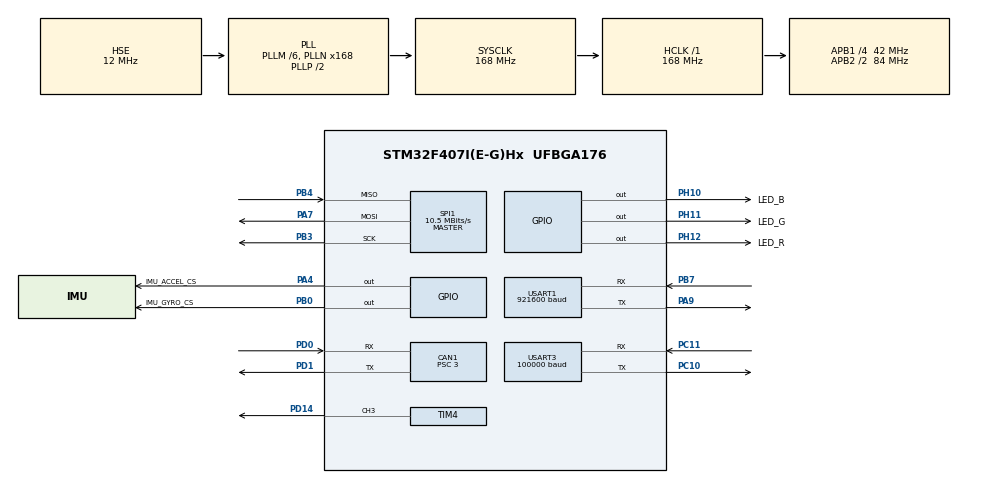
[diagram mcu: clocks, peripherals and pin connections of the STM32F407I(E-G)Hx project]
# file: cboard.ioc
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CAN1.BS1=CAN_BS1_10TQ
CAN1.BS2=CAN_BS2_3TQ
CAN1.CalculateBaudRate=1000000
CAN1.CalculateTimeQuantum=71.42857142857143
CAN1.NART=ENABLE
CAN1.Prescaler=3
CAN1.TXFP=ENABLE
Dma.Request0=USART1_TX
Dma.Request1=USART1_RX
Dma.Request2=USART3_RX
Dma.USART1_TX.0.Direction=DMA_MEMORY_TO_PERIPH
Dma.USART1_TX.0.FIFOMode=DMA_FIFOMODE_DISABLE
Dma.USART1_TX.0.Instance=DMA2_Stream7
Dma.USART1_TX.0.MemDataAlignment=DMA_MDATAALIGN_BYTE
Dma.USART1_TX.0.MemInc=DMA_MINC_ENABLE
Dma.USART1_TX.0.Mode=DMA_NORMAL
Dma.USART1_TX.0.PeriphDataAlignment=DMA_PDATAALIGN_BYTE
Dma.USART1_TX.0.PeriphInc=DMA_PINC_DISABLE
Dma.USART1_TX.0.Priority=DMA_PRIORITY_VERY_HIGH
Dma.USART1_RX.1.Direction=DMA_PERIPH_TO_MEMORY
Dma.USART1_RX.1.FIFOMode=DMA_FIFOMODE_DISABLE
Dma.USART1_RX.1.Instance=DMA2_Stream5
Dma.USART1_RX.1.MemDataAlignment=DMA_MDATAALIGN_BYTE
Dma.USART1_RX.1.MemInc=DMA_MINC_ENABLE
Dma.USART1_RX.1.Mode=DMA_NORMAL
Dma.USART1_RX.1.PeriphDataAlignment=DMA_PDATAALIGN_BYTE
Dma.USART1_RX.1.PeriphInc=DMA_PINC_DISABLE
Dma.USART1_RX.1.Priority=DMA_PRIORITY_VERY_HIGH
Dma.USART3_RX.2.Direction=DMA_PERIPH_TO_MEMORY
Dma.USART3_RX.2.FIFOMode=DMA_FIFOMODE_DISABLE
Dma.USART3_RX.2.Instance=DMA1_Stream1
Dma.USART3_RX.2.MemDataAlignment=DMA_MDATAALIGN_BYTE
Dma.USART3_RX.2.MemInc=DMA_MINC_ENABLE
Dma.USART3_RX.2.Mode=DMA_NORMAL
Dma.USART3_RX.2.PeriphDataAlignment=DMA_PDATAALIGN_BYTE
Dma.USART3_RX.2.PeriphInc=DMA_PINC_DISABLE
Dma.USART3_RX.2.Priority=DMA_PRIORITY_LOW
FREERTOS.TOTAL_HEAP_SIZE=20480
FREERTOS.Tasks01=defaultTask,24,256,StartDefaultTask,Default,NULL,Dynamic,NULL,NULL;buzzer_task,8,256,StartTask02,Default,NULL,Dynamic,NULL,NULL;led_task,8,256,StartTask03,Default,NULL,Dynamic,NULL,NULL;imu_task,32,512,imu_task_entry,As external,NULL,Dynamic,NULL,NULL;plotter_task,8,256,plotter_task,As external,NULL,Dynamic,NULL,NULL;dt7_task,40,512,StartTask06,Default,NULL,Dynamic,NULL,NULL;linkage_task,32,512,linkage_task,As external,NULL,Dynamic,NULL,NULL
Mcu.Family=STM32F4
Mcu.Name=STM32F407I(E-G)Hx
Mcu.Package=UFBGA176
NVIC.CAN1_RX0_IRQn=true\:5\:0\:true\:false\:true\:true\:true\:true\:true
NVIC.DMA1_Stream1_IRQn=true\:5\:0\:false\:false\:true\:true\:false\:true\:true
NVIC.DMA2_Stream5_IRQn=true\:5\:0\:false\:false\:true\:true\:false\:true\:true
NVIC.DMA2_Stream7_IRQn=true\:5\:0\:true\:false\:true\:true\:false\:true\:true
NVIC.PriorityGroup=NVIC_PRIORITYGROUP_4
NVIC.TIM6_DAC_IRQn=true\:15\:0\:false\:false\:true\:false\:false\:true\:true
NVIC.TimeBase=TIM6_DAC_IRQn
NVIC.TimeBaseIP=TIM6
NVIC.USART3_IRQn=true\:5\:0\:false\:false\:true\:true\:true\:true\:true
NVIC.USART1_IRQn=true\:5\:0\:false\:false\:true\:true\:true\:true\:true
PA13.Mode=Serial_Wire
PA13.Signal=SYS_JTMS-SWDIO
PA14.Mode=Serial_Wire
PA14.Signal=SYS_JTCK-SWCLK
PA4.GPIO_Label=IMU_ACCEL_CS
PA4.GPIO_Speed=GPIO_SPEED_FREQ_HIGH
PA4.PinState=GPIO_PIN_SET
PA4.Signal=GPIO_Output
PA7.Mode=Full_Duplex_Master
PA7.Signal=SPI1_MOSI
PA9.Mode=Asynchronous
PA9.Signal=USART1_TX
PD0.Mode=CAN_Activate
PD0.Signal=CAN1_RX
PD1.Mode=CAN_Activate
PD1.Signal=CAN1_TX
PB0.GPIO_Label=IMU_GYRO_CS
PB0.GPIO_Speed=GPIO_SPEED_FREQ_HIGH
PB0.PinState=GPIO_PIN_SET
PB0.Signal=GPIO_Output
PB3.Mode=Full_Duplex_Master
PB3.Signal=SPI1_SCK
PB4.Mode=Full_Duplex_Master
PB4.Signal=SPI1_MISO
PB7.Mode=Asynchronous
PB7.Signal=USART1_RX
PC10.Mode=Asynchronous
PC10.Signal=USART3_TX
PC11.Mode=Asynchronous
PC11.Signal=USART3_RX
PD14.Signal=S_TIM4_CH3
PH0-OSC_IN.Mode=HSE-External-Oscillator
PH0-OSC_IN.Signal=RCC_OSC_IN
PH1-OSC_OUT.Mode=HSE-External-Oscillator
PH1-OSC_OUT.Signal=RCC_OSC_OUT
PH10.GPIO_Label=LED_B
PH10.Signal=GPIO_Output
PH11.GPIO_Label=LED_G
PH11.Signal=GPIO_Output
PH12.GPIO_Label=LED_R
PH12.Signal=GPIO_Output
ProjectManager.HeapSize=0x200
ProjectManager.StackSize=0x400
ProjectManager.TargetToolchain=CMake
RCC.48MHZClocksFreq_Value=84000000
RCC.AHBFreq_Value=168000000
RCC.APB1CLKDivider=RCC_HCLK_DIV4
RCC.APB1Freq_Value=42000000
RCC.APB1TimFreq_Value=84000000
RCC.APB2CLKDivider=RCC_HCLK_DIV2
RCC.APB2Freq_Value=84000000
RCC.APB2TimFreq_Value=168000000
RCC.CortexFreq_Value=168000000
RCC.HCLKFreq_Value=168000000
RCC.HSE_VALUE=12000000
RCC.HSI_VALUE=16000000
RCC.LSE_VALUE=32768
RCC.PLLM=6
RCC.PLLN=168
RCC.PLLSourceVirtual=RCC_PLLSOURCE_HSE
RCC.SYSCLKFreq_VALUE=168000000
RCC.SYSCLKSource=RCC_SYSCLKSOURCE_PLLCLK
RCC.VCOOutputFreq_Value=336000000
SH.S_TIM4_CH3.0=TIM4_CH3,PWM Generation3 CH3
SPI1.BaudRatePrescaler=SPI_BAUDRATEPRESCALER_8
SPI1.CLKPolarity=SPI_POLARITY_HIGH
SPI1.CLKPhase=SPI_PHASE_2EDGE
SPI1.CalculateBaudRate=10.5 MBits/s
SPI1.Direction=SPI_DIRECTION_2LINES
SPI1.Mode=SPI_MODE_MASTER
SPI1.VirtualType=VM_MASTER
TIM4.Channel-PWM\ Generation3\ CH3=TIM_CHANNEL_3
TIM4.ClockDivision=TIM_CLOCKDIVISION_DIV1
TIM4.Period=249
TIM4.Prescaler=83
USART1.BaudRate=921600
USART1.Mode=MODE_TX_RX
USART1.VirtualMode=VM_ASYNC
USART3.BaudRate=100000
USART3.Mode=MODE_TX_RX
USART3.Parity=PARITY_EVEN
USART3.VirtualMode=VM_ASYNC
USART3.WordLength=WORDLENGTH_9B
VP_FREERTOS_VS_CMSIS_V2.Mode=CMSIS_V2
VP_SYS_VS_tim6.Mode=TIM6
board=custom

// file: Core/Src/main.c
/* USER CODE BEGIN Header */
/**
  ******************************************************************************
  * @file           : main.c
  * @brief          : Main program body
  ******************************************************************************
  * @attention
  *
  * Copyright (c) 2026 STMicroelectronics.
  * All rights reserved.
  *
  * This software is licensed under terms that can be found in the LICENSE file
  * in the root directory of this software component.
  * If no LICENSE file comes with this software, it is provided AS-IS.
  *
  ******************************************************************************
  */
/* USER CODE END Header */
#include "main.h"
#include "cmsis_os.h"
#include "dma.h"
#include "can.h"
#include "spi.h"
#include "tim.h"
#include "usart.h"
#include "gpio.h"

void SystemClock_Config(void);
void MX_FREERTOS_Init(void);

int main(void)
{

  /* MCU Configuration--------------------------------------------------------*/

  /* Reset of all peripherals, Initializes the Flash interface and the Systick. */
  HAL_Init();

  /* Configure the system clock */
  SystemClock_Config();

  /* Initialize all configured peripherals */
  MX_GPIO_Init();
  MX_DMA_Init();
  MX_CAN1_Init();
  MX_SPI1_Init();
  MX_TIM4_Init();
  MX_USART1_UART_Init();
  MX_USART3_UART_Init();

  /* Init scheduler */
  osKernelInitialize();  /* Call init function for freertos objects (in cmsis_os2.c) */
  MX_FREERTOS_Init();

  /* Start scheduler */
  osKernelStart();

  /* We should never get here as control is now taken by the scheduler */

  /* Infinite loop */
  while (1)
  {

  }
}

void SystemClock_Config(void)
{
  RCC_OscInitTypeDef RCC_OscInitStruct = {0};
  RCC_ClkInitTypeDef RCC_ClkInitStruct = {0};

  /** Configure the main internal regulator output voltage
  */
  __HAL_RCC_PWR_CLK_ENABLE();
  __HAL_PWR_VOLTAGESCALING_CONFIG(PWR_REGULATOR_VOLTAGE_SCALE1);

  /** Initializes the RCC Oscillators according to the specified parameters
  * in the RCC_OscInitTypeDef structure.
  */
  RCC_OscInitStruct.OscillatorType = RCC_OSCILLATORTYPE_HSE;
  RCC_OscInitStruct.HSEState = RCC_HSE_ON;
  RCC_OscInitStruct.PLL.PLLState = RCC_PLL_ON;
  RCC_OscInitStruct.PLL.PLLSource = RCC_PLLSOURCE_HSE;
  RCC_OscInitStruct.PLL.PLLM = 6;
  RCC_OscInitStruct.PLL.PLLN = 168;
  RCC_OscInitStruct.PLL.PLLP = RCC_PLLP_DIV2;
  RCC_OscInitStruct.PLL.PLLQ = 4;
  if (HAL_RCC_OscConfig(&RCC_OscInitStruct) != HAL_OK)
  {
    Error_Handler();
  }

  /** Initializes the CPU, AHB and APB buses clocks
  */
  RCC_ClkInitStruct.ClockType = RCC_CLOCKTYPE_HCLK|RCC_CLOCKTYPE_SYSCLK
                              |RCC_CLOCKTYPE_PCLK1|RCC_CLOCKTYPE_PCLK2;
  RCC_ClkInitStruct.SYSCLKSource = RCC_SYSCLKSOURCE_PLLCLK;
  RCC_ClkInitStruct.AHBCLKDivider = RCC_SYSCLK_DIV1;
  RCC_ClkInitStruct.APB1CLKDivider = RCC_HCLK_DIV4;
  RCC_ClkInitStruct.APB2CLKDivider = RCC_HCLK_DIV2;

  if (HAL_RCC_ClockConfig(&RCC_ClkInitStruct, FLASH_LATENCY_5) != HAL_OK)
  {
    Error_Handler();
  }
}

void HAL_TIM_PeriodElapsedCallback(TIM_HandleTypeDef *htim)
{
  if (htim->Instance == TIM6)
  {
    HAL_IncTick();
  }
}

void Error_Handler(void)
{
  __disable_irq();
  while (1)
  {
  }
}

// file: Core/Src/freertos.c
/* USER CODE BEGIN Header */
/**
  ******************************************************************************
  * File Name          : freertos.c
  * Description        : Code for freertos applications
  ******************************************************************************
  * @attention
  *
  * Copyright (c) 2026 STMicroelectronics.
  * All rights reserved.
  *
  * This software is licensed under terms that can be found in the LICENSE file
  * in the root directory of this software component.
  * If no LICENSE file comes with this software, it is provided AS-IS.
  *
  ******************************************************************************
  */
/* USER CODE END Header */

#include "FreeRTOS.h"
#include "task.h"
#include "main.h"
#include "cmsis_os.h"

/* USER CODE BEGIN Includes */

#include "buzzer.h"
#include "led.h"

/* The DT7 receiver is started once the RTOS scheduler is running. */
extern void cboard_dt7_start_receive(void);
extern void linkage_task(void *argument);

/* USER CODE END Includes */

/* Definitions for defaultTask */
osThreadId_t defaultTaskHandle;
const osThreadAttr_t defaultTask_attributes = {
  .name = "defaultTask",
  .stack_size = 256 * 4,
  .priority = (osPriority_t) osPriorityNormal,
};
/* Definitions for buzzer_task */
osThreadId_t buzzer_taskHandle;
const osThreadAttr_t buzzer_task_attributes = {
  .name = "buzzer_task",
  .stack_size = 256 * 4,
  .priority = (osPriority_t) osPriorityLow,
};
/* Definitions for led_task */
osThreadId_t led_taskHandle;
const osThreadAttr_t led_task_attributes = {
  .name = "led_task",
  .stack_size = 256 * 4,
  .priority = (osPriority_t) osPriorityLow,
};
/* Definitions for imu_task */
osThreadId_t imu_taskHandle;
const osThreadAttr_t imu_task_attributes = {
  .name = "imu_task",
  .stack_size = 512 * 4,
  .priority = (osPriority_t) osPriorityAboveNormal,
};
/* Definitions for plotter_task */
osThreadId_t plotter_taskHandle;
const osThreadAttr_t plotter_task_attributes = {
  .name = "plotter_task",
  .stack_size = 256 * 4,
  .priority = (osPriority_t) osPriorityLow,
};
/* Definitions for dt7_task */
osThreadId_t dt7_taskHandle;
const osThreadAttr_t dt7_task_attributes = {
  .name = "dt7_task",
  .stack_size = 512 * 4,
  .priority = (osPriority_t) osPriorityHigh,
};
/* Definitions for linkage_task */
osThreadId_t linkage_taskHandle;
const osThreadAttr_t linkage_task_attributes = {
  .name = "linkage_task",
  .stack_size = 512 * 4,
  .priority = (osPriority_t) osPriorityAboveNormal,
};

void StartDefaultTask(void *argument);
void StartTask02(void *argument);
void StartTask03(void *argument);
void StartTask06(void *argument);
extern void imu_task_entry(void *argument);
extern void plotter_task(void *argument);

void MX_FREERTOS_Init(void); /* (MISRA C 2004 rule 8.1) */

void MX_FREERTOS_Init(void) {

  /* Create the thread(s) */
  /* creation of defaultTask */
  defaultTaskHandle = osThreadNew(StartDefaultTask, NULL, &defaultTask_attributes);

  /* creation of buzzer_task */
  buzzer_taskHandle = osThreadNew(StartTask02, NULL, &buzzer_task_attributes);

  /* creation of led_task */
  led_taskHandle = osThreadNew(StartTask03, NULL, &led_task_attributes);

  /* creation of imu_task */
  imu_taskHandle = osThreadNew(imu_task_entry, NULL, &imu_task_attributes);

  /* creation of plotter_task */
  plotter_taskHandle = osThreadNew(plotter_task, NULL, &plotter_task_attributes);

  /* creation of dt7_task */
  dt7_taskHandle = osThreadNew(StartTask06, NULL, &dt7_task_attributes);

  /* creation of linkage_task */
  linkage_taskHandle = osThreadNew(linkage_task, NULL, &linkage_task_attributes);

}

void StartDefaultTask(void *argument)
{
  for(;;)
  {
    osDelay(1);
  }
}

void StartTask02(void *argument)
{
  /* USER CODE BEGIN StartTask02 */

  buzzer_play_startup_melody();

  /* Infinite loop */
  for(;;)
  {
    osDelay(1000);
  }
  /* USER CODE END StartTask02 */
}

void StartTask03(void *argument)
{
  /* USER CODE BEGIN StartTask03 */

  /* Infinite loop */
  for(;;)
  {
    led_show_chase_step();
    osDelay(250);
  }
  /* USER CODE END StartTask03 */
}

void StartTask06(void *argument)
{
  /* USER CODE BEGIN StartTask06 */
  cboard_dt7_start_receive();

  /* Infinite loop */
  for(;;)
  {
    /* Restart reception after a blocking UART error has been recovered. */
    cboard_dt7_start_receive();
    osDelay(1);
  }
  /* USER CODE END StartTask06 */
}
